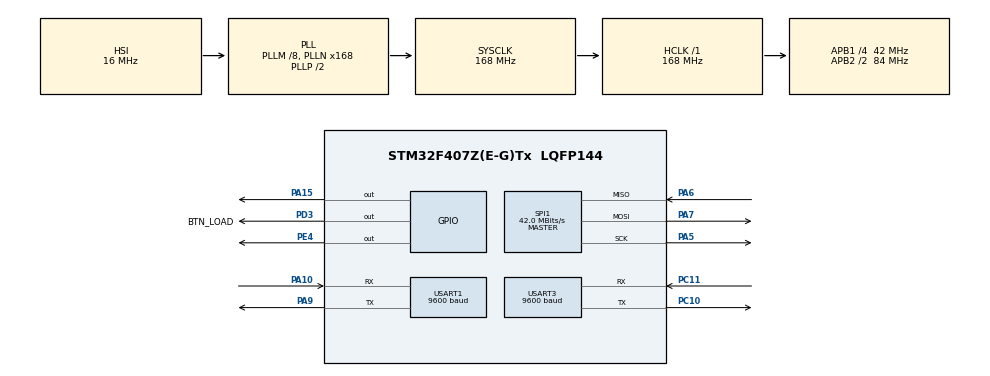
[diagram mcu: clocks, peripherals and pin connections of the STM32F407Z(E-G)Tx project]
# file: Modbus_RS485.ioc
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Mcu.Family=STM32F4
Mcu.Name=STM32F407Z(E-G)Tx
Mcu.Package=LQFP144
NVIC.PriorityGroup=NVIC_PRIORITYGROUP_4
NVIC.RCC_IRQn=true\:0\:0\:false\:false\:true\:true\:false\:true
NVIC.SPI1_IRQn=true\:0\:0\:false\:false\:true\:true\:true\:true
NVIC.TIM2_IRQn=true\:0\:0\:false\:false\:true\:true\:true\:true
NVIC.USART1_IRQn=true\:0\:0\:false\:false\:true\:true\:true\:true
NVIC.USART3_IRQn=true\:0\:0\:false\:false\:true\:true\:true\:true
PA10.Mode=Asynchronous
PA10.Signal=USART1_RX
PA13.Mode=Serial_Wire
PA13.Signal=SYS_JTMS-SWDIO
PA14.Mode=Serial_Wire
PA14.Signal=SYS_JTCK-SWCLK
PA15.Signal=GPIO_Output
PA5.Mode=Full_Duplex_Master
PA5.Signal=SPI1_SCK
PA6.Mode=Full_Duplex_Master
PA6.Signal=SPI1_MISO
PA7.Mode=Full_Duplex_Master
PA7.Signal=SPI1_MOSI
PA9.Mode=Asynchronous
PA9.Signal=USART1_TX
PC10.Mode=Asynchronous
PC10.Signal=USART3_TX
PC11.Mode=Asynchronous
PC11.Signal=USART3_RX
PD3.GPIO_Label=BTN_LOAD
PD3.Signal=GPIO_Output
PE4.Signal=GPIO_Output
PH0-OSC_IN.Mode=HSE-External-Oscillator
PH0-OSC_IN.Signal=RCC_OSC_IN
PH1-OSC_OUT.Mode=HSE-External-Oscillator
PH1-OSC_OUT.Signal=RCC_OSC_OUT
ProjectManager.HeapSize=0x200
ProjectManager.StackSize=0x400
ProjectManager.TargetToolchain=STM32CubeIDE
RCC.48MHZClocksFreq_Value=84000000
RCC.AHBFreq_Value=168000000
RCC.APB1CLKDivider=RCC_HCLK_DIV4
RCC.APB1Freq_Value=42000000
RCC.APB1TimFreq_Value=84000000
RCC.APB2CLKDivider=RCC_HCLK_DIV2
RCC.APB2Freq_Value=84000000
RCC.APB2TimFreq_Value=168000000
RCC.CortexFreq_Value=168000000
RCC.HCLKFreq_Value=168000000
RCC.HSE_VALUE=8000000
RCC.HSI_VALUE=16000000
RCC.LSE_VALUE=32768
RCC.PLLM=8
RCC.PLLN=168
RCC.SYSCLKFreq_VALUE=168000000
RCC.SYSCLKSource=RCC_SYSCLKSOURCE_PLLCLK
RCC.VCOOutputFreq_Value=336000000
SPI1.CalculateBaudRate=42.0 MBits/s
SPI1.Direction=SPI_DIRECTION_2LINES
SPI1.Mode=SPI_MODE_MASTER
SPI1.VirtualType=VM_MASTER
TIM2.Period=9
TIM2.Prescaler=8399
USART1.BaudRate=9600
USART1.VirtualMode=VM_ASYNC
USART3.BaudRate=9600
USART3.VirtualMode=VM_ASYNC
VP_TIM2_VS_ClockSourceINT.Mode=Internal
board=custom

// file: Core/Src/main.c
/* USER CODE BEGIN Header */
/**
  ******************************************************************************
  * @file           : main.c
  * @brief          : Main program body
  ******************************************************************************
  * @attention
  *
  * Copyright (c) 2024 STMicroelectronics.
  * All rights reserved.
  *
  * This software is licensed under terms that can be found in the LICENSE file
  * in the root directory of this software component.
  * If no LICENSE file comes with this software, it is provided AS-IS.
  *
  ******************************************************************************
  */
/* USER CODE END Header */
#include "main.h"

/* USER CODE BEGIN Includes */
#include "modbus.h"
/* USER CODE END Includes */

SPI_HandleTypeDef hspi1;

TIM_HandleTypeDef htim2;

UART_HandleTypeDef huart1;
UART_HandleTypeDef huart3;

/* USER CODE BEGIN PV */
uint8_t sendData[8];
/* USER CODE END PV */

void SystemClock_Config(void);
static void MX_GPIO_Init(void);
static void MX_TIM2_Init(void);
static void MX_USART1_UART_Init(void);
static void MX_USART3_UART_Init(void);
static void MX_SPI1_Init(void);

int main(void)
{

  /* MCU Configuration--------------------------------------------------------*/

  /* Reset of all peripherals, Initializes the Flash interface and the Systick. */
  HAL_Init();

  /* Configure the system clock */
  SystemClock_Config();

  /* Initialize all configured peripherals */
  MX_GPIO_Init();
  MX_TIM2_Init();
  MX_USART1_UART_Init();
  MX_USART3_UART_Init();
  MX_SPI1_Init();
  /* USER CODE BEGIN 2 */
  Modbus_Init(MODBUS_SLAVE, 0x11, 3, 10);
  Modbus_Receive(&huart3, sendData, sizeof(sendData)/sizeof(sendData[0]));
  /* USER CODE END 2 */

  /* Infinite loop */
  /* USER CODE BEGIN WHILE */
  while (1)
  {
	  Modbus_Process();
    /* USER CODE END WHILE */

  }
}

void SystemClock_Config(void)
{
  RCC_OscInitTypeDef RCC_OscInitStruct = {0};
  RCC_ClkInitTypeDef RCC_ClkInitStruct = {0};

  /** Configure the main internal regulator output voltage
  */
  __HAL_RCC_PWR_CLK_ENABLE();
  __HAL_PWR_VOLTAGESCALING_CONFIG(PWR_REGULATOR_VOLTAGE_SCALE1);

  /** Initializes the RCC Oscillators according to the specified parameters
  * in the RCC_OscInitTypeDef structure.
  */
  RCC_OscInitStruct.OscillatorType = RCC_OSCILLATORTYPE_HSI;
  RCC_OscInitStruct.HSIState = RCC_HSI_ON;
  RCC_OscInitStruct.HSICalibrationValue = RCC_HSICALIBRATION_DEFAULT;
  RCC_OscInitStruct.PLL.PLLState = RCC_PLL_ON;
  RCC_OscInitStruct.PLL.PLLSource = RCC_PLLSOURCE_HSI;
  RCC_OscInitStruct.PLL.PLLM = 8;
  RCC_OscInitStruct.PLL.PLLN = 168;
  RCC_OscInitStruct.PLL.PLLP = RCC_PLLP_DIV2;
  RCC_OscInitStruct.PLL.PLLQ = 4;
  if (HAL_RCC_OscConfig(&RCC_OscInitStruct) != HAL_OK)
  {
    Error_Handler();
  }

  /** Initializes the CPU, AHB and APB buses clocks
  */
  RCC_ClkInitStruct.ClockType = RCC_CLOCKTYPE_HCLK|RCC_CLOCKTYPE_SYSCLK
                              |RCC_CLOCKTYPE_PCLK1|RCC_CLOCKTYPE_PCLK2;
  RCC_ClkInitStruct.SYSCLKSource = RCC_SYSCLKSOURCE_PLLCLK;
  RCC_ClkInitStruct.AHBCLKDivider = RCC_SYSCLK_DIV1;
  RCC_ClkInitStruct.APB1CLKDivider = RCC_HCLK_DIV4;
  RCC_ClkInitStruct.APB2CLKDivider = RCC_HCLK_DIV2;

  if (HAL_RCC_ClockConfig(&RCC_ClkInitStruct, FLASH_LATENCY_5) != HAL_OK)
  {
    Error_Handler();
  }
}

static void MX_SPI1_Init(void)
{

  /* SPI1 parameter configuration*/
  hspi1.Instance = SPI1;
  hspi1.Init.Mode = SPI_MODE_MASTER;
  hspi1.Init.Direction = SPI_DIRECTION_2LINES;
  hspi1.Init.DataSize = SPI_DATASIZE_8BIT;
  hspi1.Init.CLKPolarity = SPI_POLARITY_LOW;
  hspi1.Init.CLKPhase = SPI_PHASE_1EDGE;
  hspi1.Init.NSS = SPI_NSS_SOFT;
  hspi1.Init.BaudRatePrescaler = SPI_BAUDRATEPRESCALER_2;
  hspi1.Init.FirstBit = SPI_FIRSTBIT_MSB;
  hspi1.Init.TIMode = SPI_TIMODE_DISABLE;
  hspi1.Init.CRCCalculation = SPI_CRCCALCULATION_DISABLE;
  hspi1.Init.CRCPolynomial = 10;
  if (HAL_SPI_Init(&hspi1) != HAL_OK)
  {
    Error_Handler();
  }

}

static void MX_TIM2_Init(void)
{

  TIM_ClockConfigTypeDef sClockSourceConfig = {0};
  TIM_MasterConfigTypeDef sMasterConfig = {0};

  htim2.Instance = TIM2;
  htim2.Init.Prescaler = 8399;
  htim2.Init.CounterMode = TIM_COUNTERMODE_UP;
  htim2.Init.Period = 9;
  htim2.Init.ClockDivision = TIM_CLOCKDIVISION_DIV1;
  htim2.Init.AutoReloadPreload = TIM_AUTORELOAD_PRELOAD_DISABLE;
  if (HAL_TIM_Base_Init(&htim2) != HAL_OK)
  {
    Error_Handler();
  }
  sClockSourceConfig.ClockSource = TIM_CLOCKSOURCE_INTERNAL;
  if (HAL_TIM_ConfigClockSource(&htim2, &sClockSourceConfig) != HAL_OK)
  {
    Error_Handler();
  }
  sMasterConfig.MasterOutputTrigger = TIM_TRGO_RESET;
  sMasterConfig.MasterSlaveMode = TIM_MASTERSLAVEMODE_DISABLE;
  if (HAL_TIMEx_MasterConfigSynchronization(&htim2, &sMasterConfig) != HAL_OK)
  {
    Error_Handler();
  }

}

static void MX_USART1_UART_Init(void)
{

  huart1.Instance = USART1;
  huart1.Init.BaudRate = 9600;
  huart1.Init.WordLength = UART_WORDLENGTH_8B;
  huart1.Init.StopBits = UART_STOPBITS_1;
  huart1.Init.Parity = UART_PARITY_NONE;
  huart1.Init.Mode = UART_MODE_TX_RX;
  huart1.Init.HwFlowCtl = UART_HWCONTROL_NONE;
  huart1.Init.OverSampling = UART_OVERSAMPLING_16;
  if (HAL_UART_Init(&huart1) != HAL_OK)
  {
    Error_Handler();
  }

}

static void MX_USART3_UART_Init(void)
{

  huart3.Instance = USART3;
  huart3.Init.BaudRate = 9600;
  huart3.Init.WordLength = UART_WORDLENGTH_8B;
  huart3.Init.StopBits = UART_STOPBITS_1;
  huart3.Init.Parity = UART_PARITY_NONE;
  huart3.Init.Mode = UART_MODE_TX_RX;
  huart3.Init.HwFlowCtl = UART_HWCONTROL_NONE;
  huart3.Init.OverSampling = UART_OVERSAMPLING_16;
  if (HAL_UART_Init(&huart3) != HAL_OK)
  {
    Error_Handler();
  }

}

static void MX_GPIO_Init(void)
{
  GPIO_InitTypeDef GPIO_InitStruct = {0};

  /* GPIO Ports Clock Enable */
  __HAL_RCC_GPIOE_CLK_ENABLE();
  __HAL_RCC_GPIOH_CLK_ENABLE();
  __HAL_RCC_GPIOA_CLK_ENABLE();
  __HAL_RCC_GPIOC_CLK_ENABLE();
  __HAL_RCC_GPIOD_CLK_ENABLE();

  /*Configure GPIO pin Output Level */
  HAL_GPIO_WritePin(GPIOE, GPIO_PIN_4, GPIO_PIN_RESET);

  /*Configure GPIO pin Output Level */
  HAL_GPIO_WritePin(GPIOA, GPIO_PIN_15, GPIO_PIN_RESET);

  /*Configure GPIO pin Output Level */
  HAL_GPIO_WritePin(BTN_LOAD_GPIO_Port, BTN_LOAD_Pin, GPIO_PIN_RESET);

  /*Configure GPIO pin : PE4 */
  GPIO_InitStruct.Pin = GPIO_PIN_4;
  GPIO_InitStruct.Mode = GPIO_MODE_OUTPUT_PP;
  GPIO_InitStruct.Pull = GPIO_NOPULL;
  GPIO_InitStruct.Speed = GPIO_SPEED_FREQ_LOW;
  HAL_GPIO_Init(GPIOE, &GPIO_InitStruct);

  /*Configure GPIO pin : PA15 */
  GPIO_InitStruct.Pin = GPIO_PIN_15;
  GPIO_InitStruct.Mode = GPIO_MODE_OUTPUT_PP;
  GPIO_InitStruct.Pull = GPIO_NOPULL;
  GPIO_InitStruct.Speed = GPIO_SPEED_FREQ_LOW;
  HAL_GPIO_Init(GPIOA, &GPIO_InitStruct);

  /*Configure GPIO pin : BTN_LOAD_Pin */
  GPIO_InitStruct.Pin = BTN_LOAD_Pin;
  GPIO_InitStruct.Mode = GPIO_MODE_OUTPUT_PP;
  GPIO_InitStruct.Pull = GPIO_NOPULL;
  GPIO_InitStruct.Speed = GPIO_SPEED_FREQ_LOW;
  HAL_GPIO_Init(BTN_LOAD_GPIO_Port, &GPIO_InitStruct);

}

/* USER CODE BEGIN 4 */
void HAL_UARTEx_RxEventCallback(UART_HandleTypeDef *huart, uint16_t Size)
{
	Modbus_Receive_Callback(huart);
}
/* USER CODE END 4 */

void Error_Handler(void)
{
  __disable_irq();
  while (1)
  {
  }
}
